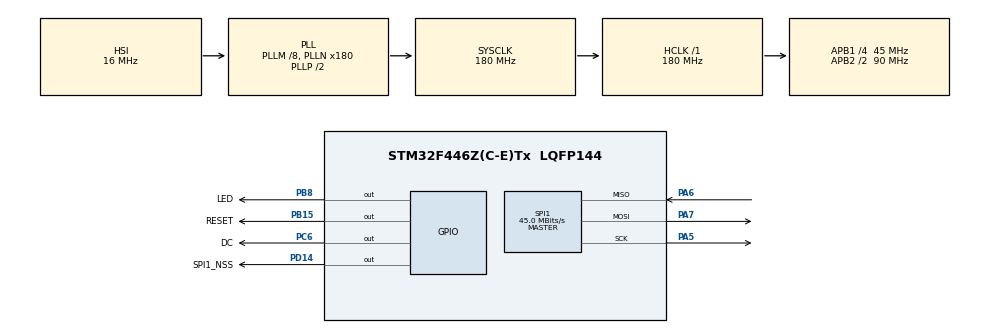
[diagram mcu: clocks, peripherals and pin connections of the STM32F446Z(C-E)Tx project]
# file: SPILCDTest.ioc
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Mcu.Family=STM32F4
Mcu.Name=STM32F446Z(C-E)Tx
Mcu.Package=LQFP144
NVIC.PriorityGroup=NVIC_PRIORITYGROUP_4
PA5.GPIO_PuPd=GPIO_PULLDOWN
PA5.Mode=Full_Duplex_Master
PA5.Signal=SPI1_SCK
PA6.GPIO_PuPd=GPIO_PULLDOWN
PA6.Mode=Full_Duplex_Master
PA6.Signal=SPI1_MISO
PA7.GPIO_PuPd=GPIO_PULLDOWN
PA7.Mode=Full_Duplex_Master
PA7.Signal=SPI1_MOSI
PB15.GPIO_Label=RESET
PB15.GPIO_PuPd=GPIO_PULLUP
PB15.GPIO_Speed=GPIO_SPEED_FREQ_VERY_HIGH
PB15.PinState=GPIO_PIN_SET
PB15.Signal=GPIO_Output
PB8.GPIO_Label=LED
PB8.GPIO_PuPd=GPIO_PULLUP
PB8.GPIO_Speed=GPIO_SPEED_FREQ_VERY_HIGH
PB8.PinState=GPIO_PIN_SET
PB8.Signal=GPIO_Output
PC6.GPIO_Label=DC
PC6.GPIO_PuPd=GPIO_PULLUP
PC6.GPIO_Speed=GPIO_SPEED_FREQ_VERY_HIGH
PC6.PinState=GPIO_PIN_SET
PC6.Signal=GPIO_Output
PD14.GPIO_Label=SPI1_NSS
PD14.GPIO_PuPd=GPIO_PULLUP
PD14.GPIO_Speed=GPIO_SPEED_FREQ_VERY_HIGH
PD14.PinState=GPIO_PIN_SET
PD14.Signal=GPIO_Output
ProjectManager.HeapSize=0x200
ProjectManager.StackSize=0x400
ProjectManager.TargetToolchain=STM32CubeIDE
RCC.AHBFreq_Value=180000000
RCC.APB1CLKDivider=RCC_HCLK_DIV4
RCC.APB1Freq_Value=45000000
RCC.APB1TimFreq_Value=90000000
RCC.APB2CLKDivider=RCC_HCLK_DIV2
RCC.APB2Freq_Value=90000000
RCC.APB2TimFreq_Value=180000000
RCC.CortexFreq_Value=180000000
RCC.HCLKFreq_Value=180000000
RCC.PLLM=8
RCC.PLLN=180
RCC.SYSCLKFreq_VALUE=180000000
RCC.SYSCLKSource=RCC_SYSCLKSOURCE_PLLCLK
RCC.USBFreq_Value=180000000
RCC.VCOOutputFreq_Value=360000000
SPI1.BaudRatePrescaler=SPI_BAUDRATEPRESCALER_2
SPI1.CalculateBaudRate=45.0 MBits/s
SPI1.Direction=SPI_DIRECTION_2LINES
SPI1.Mode=SPI_MODE_MASTER
SPI1.VirtualType=VM_MASTER
board=custom

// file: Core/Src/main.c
/* USER CODE BEGIN Header */
/**
  ******************************************************************************
  * @file           : main.c
  * @brief          : Main program body
  ******************************************************************************
  * @attention
  *
  * <h2><center>&copy; Copyright (c) 2019 STMicroelectronics.
  * All rights reserved.</center></h2>
  *
  * This software component is licensed by ST under BSD 3-Clause license,
  * the "License"; You may not use this file except in compliance with the
  * License. You may obtain a copy of the License at:
  *                        opensource.org/licenses/BSD-3-Clause
  *
  ******************************************************************************
  */
/* USER CODE END Header */

#include "main.h"

/* USER CODE BEGIN Includes */
#include "ili9341.h"
/* USER CODE END Includes */

SPI_HandleTypeDef hspi1;

void SystemClock_Config(void);
static void MX_GPIO_Init(void);
static void MX_SPI1_Init(void);

/* USER CODE BEGIN 0 */
#define CLSIZ 5
uint16_t color[CLSIZ] = {BLACK, BLUE, RED, GREEN, WHITE};
/* USER CODE END 0 */

int main(void)
{
  /* USER CODE BEGIN 1 */
	uint32_t idx = 0;
  /* USER CODE END 1 */

  /* MCU Configuration--------------------------------------------------------*/

  /* Reset of all peripherals, Initializes the Flash interface and the Systick. */
  HAL_Init();

  /* Configure the system clock */
  SystemClock_Config();

  /* Initialize all configured peripherals */
  MX_GPIO_Init();
  MX_SPI1_Init();
  /* USER CODE BEGIN 2 */
  ILI9341_Init();
  /* USER CODE END 2 */

  /* Infinite loop */
  while (1)
  {

    /* USER CODE BEGIN 3 */
	  ILI9341_Fill(color[idx++]);
	  idx = (idx >= CLSIZ) ? 0 : idx;
	  HAL_Delay(100);
  }
  /* USER CODE END 3 */
}

void SystemClock_Config(void)
{
  RCC_OscInitTypeDef RCC_OscInitStruct = {0};
  RCC_ClkInitTypeDef RCC_ClkInitStruct = {0};

  /** Configure the main internal regulator output voltage
  */
  __HAL_RCC_PWR_CLK_ENABLE();
  __HAL_PWR_VOLTAGESCALING_CONFIG(PWR_REGULATOR_VOLTAGE_SCALE1);
  /** Initializes the CPU, AHB and APB busses clocks
  */
  RCC_OscInitStruct.OscillatorType = RCC_OSCILLATORTYPE_HSI;
  RCC_OscInitStruct.HSIState = RCC_HSI_ON;
  RCC_OscInitStruct.HSICalibrationValue = RCC_HSICALIBRATION_DEFAULT;
  RCC_OscInitStruct.PLL.PLLState = RCC_PLL_ON;
  RCC_OscInitStruct.PLL.PLLSource = RCC_PLLSOURCE_HSI;
  RCC_OscInitStruct.PLL.PLLM = 8;
  RCC_OscInitStruct.PLL.PLLN = 180;
  RCC_OscInitStruct.PLL.PLLP = RCC_PLLP_DIV2;
  RCC_OscInitStruct.PLL.PLLQ = 2;
  RCC_OscInitStruct.PLL.PLLR = 2;
  if (HAL_RCC_OscConfig(&RCC_OscInitStruct) != HAL_OK)
  {
    Error_Handler();
  }
  /** Activate the Over-Drive mode
  */
  if (HAL_PWREx_EnableOverDrive() != HAL_OK)
  {
    Error_Handler();
  }
  /** Initializes the CPU, AHB and APB busses clocks
  */
  RCC_ClkInitStruct.ClockType = RCC_CLOCKTYPE_HCLK|RCC_CLOCKTYPE_SYSCLK
                              |RCC_CLOCKTYPE_PCLK1|RCC_CLOCKTYPE_PCLK2;
  RCC_ClkInitStruct.SYSCLKSource = RCC_SYSCLKSOURCE_PLLCLK;
  RCC_ClkInitStruct.AHBCLKDivider = RCC_SYSCLK_DIV1;
  RCC_ClkInitStruct.APB1CLKDivider = RCC_HCLK_DIV4;
  RCC_ClkInitStruct.APB2CLKDivider = RCC_HCLK_DIV2;

  if (HAL_RCC_ClockConfig(&RCC_ClkInitStruct, FLASH_LATENCY_5) != HAL_OK)
  {
    Error_Handler();
  }
}

static void MX_SPI1_Init(void)
{

  /* SPI1 parameter configuration*/
  hspi1.Instance = SPI1;
  hspi1.Init.Mode = SPI_MODE_MASTER;
  hspi1.Init.Direction = SPI_DIRECTION_2LINES;
  hspi1.Init.DataSize = SPI_DATASIZE_8BIT;
  hspi1.Init.CLKPolarity = SPI_POLARITY_LOW;
  hspi1.Init.CLKPhase = SPI_PHASE_1EDGE;
  hspi1.Init.NSS = SPI_NSS_SOFT;
  hspi1.Init.BaudRatePrescaler = SPI_BAUDRATEPRESCALER_2;
  hspi1.Init.FirstBit = SPI_FIRSTBIT_MSB;
  hspi1.Init.TIMode = SPI_TIMODE_DISABLE;
  hspi1.Init.CRCCalculation = SPI_CRCCALCULATION_DISABLE;
  hspi1.Init.CRCPolynomial = 10;
  if (HAL_SPI_Init(&hspi1) != HAL_OK)
  {
    Error_Handler();
  }

}

static void MX_GPIO_Init(void)
{
  GPIO_InitTypeDef GPIO_InitStruct = {0};

  /* GPIO Ports Clock Enable */
  __HAL_RCC_GPIOA_CLK_ENABLE();
  __HAL_RCC_GPIOB_CLK_ENABLE();
  __HAL_RCC_GPIOD_CLK_ENABLE();
  __HAL_RCC_GPIOC_CLK_ENABLE();

  /*Configure GPIO pin Output Level */
  HAL_GPIO_WritePin(GPIOB, RESET_Pin|LED_Pin, GPIO_PIN_SET);

  /*Configure GPIO pin Output Level */
  HAL_GPIO_WritePin(SPI1_NSS_GPIO_Port, SPI1_NSS_Pin, GPIO_PIN_SET);

  /*Configure GPIO pin Output Level */
  HAL_GPIO_WritePin(DC_GPIO_Port, DC_Pin, GPIO_PIN_SET);

  /*Configure GPIO pins : RESET_Pin LED_Pin */
  GPIO_InitStruct.Pin = RESET_Pin|LED_Pin;
  GPIO_InitStruct.Mode = GPIO_MODE_OUTPUT_PP;
  GPIO_InitStruct.Pull = GPIO_PULLUP;
  GPIO_InitStruct.Speed = GPIO_SPEED_FREQ_VERY_HIGH;
  HAL_GPIO_Init(GPIOB, &GPIO_InitStruct);

  /*Configure GPIO pin : SPI1_NSS_Pin */
  GPIO_InitStruct.Pin = SPI1_NSS_Pin;
  GPIO_InitStruct.Mode = GPIO_MODE_OUTPUT_PP;
  GPIO_InitStruct.Pull = GPIO_PULLUP;
  GPIO_InitStruct.Speed = GPIO_SPEED_FREQ_VERY_HIGH;
  HAL_GPIO_Init(SPI1_NSS_GPIO_Port, &GPIO_InitStruct);

  /*Configure GPIO pin : DC_Pin */
  GPIO_InitStruct.Pin = DC_Pin;
  GPIO_InitStruct.Mode = GPIO_MODE_OUTPUT_PP;
  GPIO_InitStruct.Pull = GPIO_PULLUP;
  GPIO_InitStruct.Speed = GPIO_SPEED_FREQ_VERY_HIGH;
  HAL_GPIO_Init(DC_GPIO_Port, &GPIO_InitStruct);

}

void Error_Handler(void)
{
  /* USER CODE BEGIN Error_Handler_Debug */
  /* User can add his own implementation to report the HAL error return state */
	while (1)
		;
  /* USER CODE END Error_Handler_Debug */
}

/************************ (C) COPYRIGHT STMicroelectronics *****END OF FILE****/
